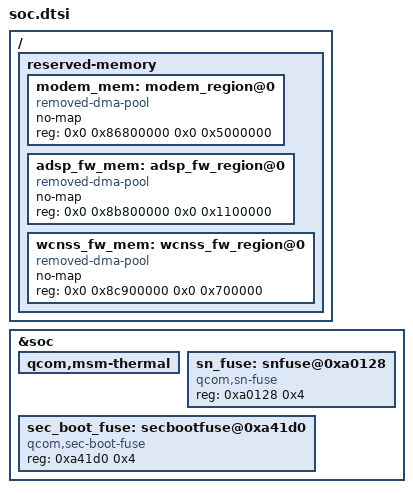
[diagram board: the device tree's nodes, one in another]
/ {
	reserved-memory {
		modem_mem: modem_region@0 {
			compatible = "removed-dma-pool";
			no-map;
			reg = <0x0 0x86800000 0x0 0x5000000>;
		};

		adsp_fw_mem: adsp_fw_region@0 {
			compatible = "removed-dma-pool";
			no-map;
			reg = <0x0 0x8b800000 0x0 0x1100000>;
		};

		wcnss_fw_mem: wcnss_fw_region@0 {
			compatible = "removed-dma-pool";
			no-map;
			reg = <0x0 0x8c900000 0x0 0x700000>;
		};
	};
};

&soc {
	qcom,msm-thermal {
		/delete-property/ qcom,therm-reset-temp;
	};
	
	sn_fuse: snfuse@0xa0128 {
		compatible = "qcom,sn-fuse";
		reg = <0xa0128 0x4>;
		reg-names = "sn-base";
	};

	sec_boot_fuse: secbootfuse@0xa41d0 {
		compatible = "qcom,sec-boot-fuse";
		reg = <0xa41d0 0x4>;
		reg-names = "sec-boot-base";
	};
};
